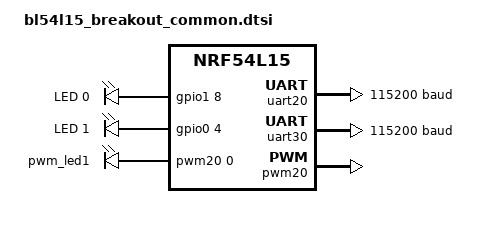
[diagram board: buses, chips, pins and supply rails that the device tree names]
/*
 * Copyright (c) 2024 Nordic Semiconductor ASA
 * Copyright (c) 2025 Jamie M.
 *
 * SPDX-License-Identifier: Apache-2.0
 */

#include "bl54l15_breakout_nrf54l15-pinctrl.dtsi"

/ {
	leds {
		compatible = "gpio-leds";
		led0: led_0 {
			gpios = <&gpio1 8 GPIO_ACTIVE_HIGH>;
			label = "LED 0";
		};
		led1: led_1 {
			gpios = <&gpio0 4 GPIO_ACTIVE_HIGH>;
			label = "LED 1";
		};
	};

	pwmleds {
		compatible = "pwm-leds";
		/*
		 * PWM signal can be exposed on GPIO pin only within same domain.
		 * There is only one domain which contains both PWM and GPIO:
		 * PWM20/21/22 and GPIO Port P1.
		 * Only LEDs connected to P1 can work with PWM, for example LED1.
		 */
		pwm_led1: pwm_led_1 {
			pwms = <&pwm20 0 PWM_MSEC(20) PWM_POLARITY_NORMAL>;
		};
	};

	aliases {
		led0 = &led0;
		led1 = &led1;
		watchdog0 = &wdt31;
	};
};

&uart20 {
	current-speed = <115200>;
	pinctrl-0 = <&uart20_default>;
	pinctrl-1 = <&uart20_sleep>;
	pinctrl-names = "default", "sleep";
};

&uart30 {
	current-speed = <115200>;
	pinctrl-0 = <&uart30_default>;
	pinctrl-1 = <&uart30_sleep>;
	pinctrl-names = "default", "sleep";
};

&pwm20 {
	status = "okay";
	pinctrl-0 = <&pwm20_default>;
	pinctrl-1 = <&pwm20_sleep>;
	pinctrl-names = "default", "sleep";
};
